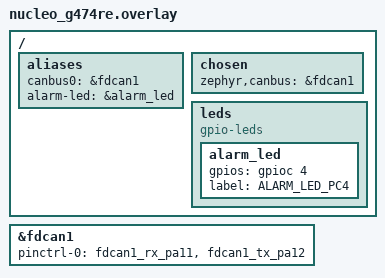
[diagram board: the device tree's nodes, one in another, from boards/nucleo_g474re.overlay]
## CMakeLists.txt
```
cmake_minimum_required(VERSION 3.20.0)

# ============================================================
# Zephyr base
# ============================================================
find_package(Zephyr REQUIRED HINTS $ENV{ZEPHYR_BASE})

project(supervisor_node_mcu LANGUAGES C CXX)

# ============================================================
# C++ STANDARD
# ============================================================
set(CMAKE_CXX_STANDARD 20)
set(CMAKE_CXX_STANDARD_REQUIRED ON)
set(CMAKE_CXX_EXTENSIONS OFF)

# ============================================================
# INCLUDE PATHS
# ============================================================
target_include_directories(app PRIVATE
    include
)

# ============================================================
# SOURCE FILES
# ============================================================
target_sources(app PRIVATE
    src/main.cpp
    src/gpio_overlay.cpp
    src/canfd.cpp
    src/heartbeat_monitoring.cpp
    src/alarm.cpp
)

# ============================================================
# COMPILER SAFETY FLAGS
# ============================================================
# NOTE on -Wpedantic: intentionally NOT requested. Zephyr 3.7 LTS's own
# public headers (kernel.h, sys_clock.h, sw_isr_table.h, toolchain/gcc.h,
# newlib's stdint.h/string.h, ...) rely on GNU C extensions (compound
# literals, anonymous structs, flexible array members, #include_next,
# named variadic macros) that are not ISO-C++-pedantic-clean. On this
# toolchain (arm-zephyr-eabi-g++, SDK 0.17.2) several of these specific
# diagnostics (-Wvariadic-macros, and two pedantic checks GCC emits with
# a bare "[-Werror]" tag rather than "[-Wpedantic]") do not respond to
# -Wno-error=pedantic, so they cannot be selectively demoted -- the only
# reliable fix is to not enable -Wpedantic in the first place. This is a
# documented limitation of building Zephyr with a strict ISO C++
# frontend, not a defect in application code.
#
# -Wno-error=format: one Zephyr __ASSERT() macro (spinlock.h) passes a
# k_spinlock* where %p expects void*; again upstream, outside app control.
#
# -Wno-error=missing-field-initializers: Zephyr's K_MSGQ_DEFINE() macro
# (Z_MSGQ_INITIALIZER in kernel.h) does not explicitly initialize every
# struct k_msgq field, relying on C99 zero-fill semantics that -Wextra
# flags under C++. Upstream macro behaviour, not application code.
target_compile_options(app PRIVATE
    -Wall
    -Wextra
    -Werror
    -Wno-error=format
    -Wno-error=missing-field-initializers
)

# ============================================================
# OPTIONAL: STRICT MISRA-LIKE BUILD HARDENING
# ============================================================
target_compile_options(app PRIVATE
    -fno-exceptions
    -fno-rtti
)
```

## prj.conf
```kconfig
# ============================================================
# BASIC KERNEL CONFIGURATION
# ============================================================
CONFIG_MAIN_STACK_SIZE=2048
CONFIG_IDLE_STACK_SIZE=512

CONFIG_SYSTEM_WORKQUEUE_STACK_SIZE=2048

CONFIG_MULTITHREADING=y
CONFIG_NUM_COOP_PRIORITIES=16
CONFIG_NUM_PREEMPT_PRIORITIES=16

CONFIG_TIMESLICING=y
CONFIG_TIMESLICE_SIZE=0

CONFIG_TICKLESS_KERNEL=y
CONFIG_SYS_CLOCK_TICKS_PER_SEC=1000


# ============================================================
# MEMORY CONFIGURATION (STRICT NO HEAP POLICY)
# ============================================================
CONFIG_HEAP_MEM_POOL_SIZE=0
CONFIG_MAIN_STACK_SIZE=2048

CONFIG_INIT_STACKS=y


# ============================================================
# C++ SUPPORT (C++20 EMBEDDED)
# ============================================================
# NOTE: CONFIG_CPLUSPLUS was removed - undefined symbol per the
# build warnings. Using CONFIG_CPP=y instead. If this still
# warns as undefined, run:
#   grep -rn "^config CPP\b" $ZEPHYR_BASE/subsys/cpp/Kconfig
# and swap in whatever symbol name it reports.
CONFIG_CPP=y
CONFIG_STD_CPP20=y

CONFIG_NEWLIB_LIBC=y
CONFIG_NEWLIB_LIBC_NANO=y

CONFIG_REQUIRES_FULL_LIBC=y


# ============================================================
# LOGGING & DEBUGGING
# ============================================================
CONFIG_LOG=y
CONFIG_LOG_MODE_IMMEDIATE=y
CONFIG_LOG_DEFAULT_LEVEL=3

CONFIG_PRINTK=y
CONFIG_ASSERT=y
CONFIG_DEBUG=y

CONFIG_THREAD_NAME=y
CONFIG_THREAD_MONITOR=y


# ============================================================
# GPIO SUPPORT
# ============================================================
CONFIG_GPIO=y


# ============================================================
# CAN / FDCAN SUPPORT (CRITICAL)
# ============================================================
CONFIG_CAN=y
CONFIG_CAN_FD_MODE=y
CONFIG_CAN_INIT_PRIORITY=80



# ============================================================
# STM32 DEVICE SUPPORT
# ============================================================
# NOTE: CONFIG_SOC_SERIES_STM32G4X / CONFIG_SOC_STM32G474XX were
# removed. These are NOT user-configurable Kconfig symbols (they
# have no "prompt" in Kconfig); they are derived automatically
# from the BOARD=nucleo_g474re selection. Setting them explicitly
# in prj.conf causes a hard Kconfig error in this Zephyr version.
CONFIG_CLOCK_CONTROL=y
CONFIG_PINCTRL=y


# ============================================================
# THREADING & SCHEDULING SAFETY
# ============================================================
# NOTE: CONFIG_PREEMPT_ENABLED and CONFIG_SCHED_DUMB removed.
# Both are silent Kconfig symbols (no prompt) in this Zephyr
# version - they're derived automatically, not user-settable.
CONFIG_THREAD_STACK_INFO=y
CONFIG_THREAD_RUNTIME_STATS=y


# ============================================================
# TIME & DELAY
# ============================================================
CONFIG_SYS_CLOCK_EXISTS=y
CONFIG_TIMEOUT_64BIT=y


# ============================================================
# SAFETY FEATURES
# ============================================================
CONFIG_FAULT_DUMP=2


# ============================================================
# OPTIONAL PERFORMANCE / CAN DEBUG
# ============================================================
CONFIG_CAN_RX_TIMESTAMP=y


# ============================================================
# BOOT CONFIG
# ============================================================
CONFIG_BOOT_BANNER=y
CONFIG_BOOT_DELAY=0
```

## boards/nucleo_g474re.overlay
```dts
/*
 * SPDX-License-Identifier: Apache-2.0
 *
 * Supervisor Node MCU
 * Board : STM32 NUCLEO-G474RE
 * RTOS  : Zephyr 3.7 LTS
 */

/ {
    aliases {
        canbus0 = &fdcan1;
        alarm-led = &alarm_led;
    };

    chosen {
        zephyr,canbus = &fdcan1;
    };
};

/* ============================================================
 * FDCAN1 CONFIGURATION (CAN BUS)
 * PA11 -> RX
 * PA12 -> TX
 * ============================================================
 */
&fdcan1 {
    status = "okay";
    pinctrl-0 = <&fdcan1_rx_pa11 &fdcan1_tx_pa12>;
    pinctrl-names = "default";
};

/* ============================================================
 * GPIO CONFIGURATION
 * PC4 -> ALARM / HEARTBEAT LED
 * ============================================================
 */
/ {
    leds {
        compatible = "gpio-leds";

        alarm_led: alarm_led {
            gpios = <&gpioc 4 GPIO_ACTIVE_HIGH>;
            label = "ALARM_LED_PC4";
        };
    };
};
```

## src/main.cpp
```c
#include <zephyr/kernel.h>
#include <zephyr/logging/log.h>

#include "gpio_overlay.hpp"
#include "canfd.hpp"
#include "heartbeat_monitoring.hpp"
#include "alarm.hpp"

LOG_MODULE_REGISTER(supervisor_node, LOG_LEVEL_INF);

/* ============================================================
 * SYSTEM LIMITS (NO MAGIC NUMBERS)
 * ============================================================
 */
static constexpr std::uint16_t kFlowMin_mL_min  = 350U;
static constexpr std::uint16_t kFlowMax_mL_min  = 450U;

static constexpr std::uint16_t kPressureMin_mmHg = 100U;
static constexpr std::uint16_t kPressureMax_mmHg = 180U;

/* ============================================================
 * SHARED SENSOR DATA (UPDATED VIA CAN RX)
 * ============================================================
 * NOTE: deliberately at TU (external) linkage, not inside an
 * unnamed namespace. canfd.cpp declares these `extern` and
 * writes to them from CanFd::DecodeRx() on CAN RX of the
 * pressure/flow frames; an unnamed namespace would give them
 * internal linkage and silently create a second, disconnected
 * copy per translation unit (link-time undefined reference).
 */
volatile std::uint16_t g_flow_value = 0U;
volatile std::uint16_t g_pressure_value = 0U;

/* ============================================================
 * THREAD STACKS
 * ============================================================
 */
K_THREAD_STACK_DEFINE(can_stack, 2048);
K_THREAD_STACK_DEFINE(safety_stack, 2048);
K_THREAD_STACK_DEFINE(hb_stack, 1024);

static struct k_thread can_thread;
static struct k_thread safety_thread;
static struct k_thread hb_thread;

/* ============================================================
 * CAN RX THREAD (100ms cycle)
 * ============================================================
 */
static void CanThread()
{
    LOG_INF("CAN thread started");

    CanFd::ProcessRx();
}

/* ============================================================
 * SAFETY EVALUATION THREAD (1 second cycle)
 * ============================================================
 * Checks:
 * - Combined fault: pressure HIGH (above max) together with
 *   flow LOW (below min) at the same time.
 * - Independent excursions of either signal alone are NOT a
 *   fault; only the simultaneous high-pressure / low-flow
 *   combination triggers STOP + ALARM.
 * ============================================================
 */
static void SafetyThread()
{
    LOG_INF("Safety thread started");

    while (true)
    {
        bool pressure_high = (g_pressure_value > kPressureMax_mmHg);
        bool flow_low       = (g_flow_value < kFlowMin_mL_min);

        bool combined_fault = pressure_high && flow_low;

        if (combined_fault)
        {
            LOG_ERR("Safety fault detected (pressure high + flow low) -> STOP MOTOR");

            CanFd::SendStopMotor();

            /* Out-of-range process value is a safety-critical fault:
             * latch PC4 ALARM until the next MCU reset. */
            Alarm::Trigger();
        }

        HeartbeatMonitoring::Evaluate();

        k_sleep(K_MSEC(1000));
    }
}

/* ============================================================
 * HEARTBEAT THREAD (1 second cycle)
 * ============================================================
 */
static void HeartbeatThread()
{
    LOG_INF("Heartbeat thread started");

    while (true)
    {
        /* If the alarm has latched, PC4 must stay solid ON and must
         * never be touched again until a hardware reset occurs. */
        if (!Alarm::IsLatched())
        {
            /* Future: LED blink + system alive monitoring */
        }

        k_sleep(K_MSEC(1000));
    }
}

/* ============================================================
 * MAIN
 * ============================================================
 */
int main()
{
    LOG_INF("Supervisor Node Booting...");

    /* INIT HARDWARE */
    if (!GpioOverlay::Init())
    {
        LOG_ERR("GPIO Init failed");
        return -1;
    }

    if (!Alarm::Init())
    {
        LOG_ERR("Alarm Init failed");
        return -1;
    }

    if (!CanFd::Init())
    {
        LOG_ERR("CAN Init failed");
        return -1;
    }

    HeartbeatMonitoring::Init();

    /* ========================================================
     * START THREADS
     * ========================================================
     */
    k_thread_create(&can_thread,
                    can_stack,
                    K_THREAD_STACK_SIZEOF(can_stack),
                    (k_thread_entry_t)CanThread,
                    nullptr, nullptr, nullptr,
                    5, 0, K_NO_WAIT);

    k_thread_create(&safety_thread,
                    safety_stack,
                    K_THREAD_STACK_SIZEOF(safety_stack),
                    (k_thread_entry_t)SafetyThread,
                    nullptr, nullptr, nullptr,
                    5, 0, K_NO_WAIT);

    k_thread_create(&hb_thread,
                    hb_stack,
                    K_THREAD_STACK_SIZEOF(hb_stack),
                    (k_thread_entry_t)HeartbeatThread,
                    nullptr, nullptr, nullptr,
                    5, 0, K_NO_WAIT);

    LOG_INF("Supervisor Node Running");

    while (true)
    {
        k_sleep(K_FOREVER);
    }

    return 0;
}
```

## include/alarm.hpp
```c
#ifndef ALARM_HPP
#define ALARM_HPP

/**
 * ============================================================
 * ALARM MODULE
 * ============================================================
 * Board : STM32 NUCLEO-G474RE
 * RTOS  : Zephyr 3.7 LTS
 *
 * Responsibility:
 * - Latch the system into an ALARM state (PC4 LED ON)
 *   whenever a safety-critical fault condition is reported
 *   by any other module (flow/pressure out of range, missed
 *   heartbeats, E-STOP, etc.).
 * - Once latched, the alarm output (PC4) stays ACTIVE and
 *   cannot be cleared by software. The only way to clear the
 *   alarm is a full MCU reset (pressing the on-board NRST
 *   button), which re-runs static initialization and Init().
 *
 * DESIGN PATTERN: State Pattern
 * - AlarmState::kArmed  -> normal operation, PC4 OFF.
 * - AlarmState::kLatched -> fault occurred, PC4 ON, and the
 *   state machine refuses every transition back to kArmed
 *   from software. Only Init() (invoked at boot / after a
 *   hardware reset) may return the state machine to kArmed.
 *
 * RULE:
 * - No business logic (sensor evaluation, CAN decoding) here.
 * - Only alarm state management + GPIO latch behaviour.
 * ============================================================
 */

#include <cstdint>

/**
 * @brief Alarm state machine states (State design pattern).
 */
enum class AlarmState : std::uint8_t
{
    kArmed   = 0U, ///< Normal operation, alarm output inactive.
    kLatched = 1U  ///< Fault latched, alarm output active until reset.
};

/**
 * @brief Latching safety alarm driver.
 *
 * Drives the ALARM LED on PC4 through GpioOverlay. Implements a
 * latch: once Trigger() is called, the alarm remains active
 * (PC4 HIGH) regardless of how many times Trigger()/Clear() is
 * subsequently called from software. The latch can only be
 * removed by a physical MCU reset (NRST button), since Init()
 * is the sole entry point that resets the internal state, and
 * Init() is only ever invoked once at boot from main().
 */
class Alarm
{
public:
    /**
     * @brief Initialize the alarm module.
     *
     * Must be called exactly once at boot, after
     * GpioOverlay::Init(). Sets the state machine to
     * AlarmState::kArmed and ensures PC4 is OFF.
     *
     * @return true if initialization succeeded.
     */
    static bool Init();

    /**
     * @brief Trigger (latch) the alarm.
     *
     * Drives PC4 HIGH and transitions the state machine to
     * AlarmState::kLatched. Safe to call repeatedly / from
     * multiple threads (e.g. SafetyThread and
     * HeartbeatMonitoring) — once latched, further calls are
     * a no-op.
     */
    static void Trigger();

    /**
     * @brief Query whether the alarm is currently latched.
     * @return true if the alarm has been triggered and not
     *         yet cleared by a hardware reset.
     */
    static bool IsLatched();

private:
    static AlarmState state_;
    static bool       initialized_;
};

#endif // ALARM_HPP
```

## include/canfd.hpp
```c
#ifndef CANFD_HPP
#define CANFD_HPP

/**
 * ============================================================
 * CANFD PROTOCOL LAYER
 * ============================================================
 * Board : STM32 NUCLEO-G474RE
 * RTOS  : Zephyr 3.7 LTS
 *
 * Responsibility:
 * - Handle CAN RX/TX
 * - Decode system messages
 * - Route data to application modules
 * - Send control commands (START / STOP / E-STOP)
 *
 * RULE:
 * - No business logic here
 * - Only protocol handling + dispatch
 * ============================================================
 */

#include <cstdint>

class CanFd
{
public:
    /**
     * @brief Initialize CAN peripheral and filters
     * @return true if success
     */
    static bool Init();

    /**
     * @brief Poll or wait for CAN messages (thread loop entry)
     */
    static void ProcessRx();

    /**
     * @brief Send START_MOTOR command (0x400)
     */
    static void SendStartMotor();

    /**
     * @brief Send STOP_MOTOR command (0x100)
     */
    static void SendStopMotor();

    /**
     * @brief Send E-STOP broadcast (0x101)
     */
    static void SendEStopBroadcast();

    /* ============================================================
     * RX QUEUE DEPTH (NO MAGIC NUMBERS)
     * ============================================================
     * Public because it is needed by the file-scope K_MSGQ_DEFINE()
     * in canfd.cpp, which must be sized at compile time outside the
     * class body. Not part of the protocol contract with other
     * modules — purely an implementation-tuning constant.
     */
    static constexpr std::uint16_t kRxQueueDepth = 10U;

private:
    /* ============================================================
     * CAN IDs (NO MAGIC NUMBERS)
     * ============================================================
     */
    static constexpr std::uint32_t kStartMotorId = 0x400U;
    static constexpr std::uint32_t kStopMotorId  = 0x100U;
    static constexpr std::uint32_t kEstopId      = 0x101U;

    static constexpr std::uint32_t kSensorHbId   = 0x200U;
    static constexpr std::uint32_t kMotorHbId    = 0x201U;
    static constexpr std::uint32_t kPressureId    = 0x300U;
    static constexpr std::uint32_t kFlowId        = 0x301U;

    /* ============================================================
     * RX QUEUE TUNING (NO MAGIC NUMBERS)
     * ============================================================
     */
    static constexpr std::uint32_t kRxPollTimeoutMs = 10U;
    static constexpr std::uint32_t kTxTimeoutMs     = 10U;

    /* Accept-all filter: zero mask matches every standard CAN ID. */
    static constexpr std::uint32_t kAcceptAllId   = 0U;
    static constexpr std::uint32_t kAcceptAllMask = 0U;

    /**
     * @brief Internal RX dispatcher
     * @param id CAN ID
     * @param data pointer to payload
     * @param len payload length
     */
    static void DecodeRx(std::uint32_t id, const std::uint8_t* data, std::uint8_t len);
};

#endif // CANFD_HPP
```

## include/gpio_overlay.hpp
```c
#ifndef GPIO_OVERLAY_HPP
#define GPIO_OVERLAY_HPP

/**
 * ============================================================
 * GPIO OVERLAY (HARDWARE ABSTRACTION LAYER)
 * ============================================================
 * Board : STM32 NUCLEO-G474RE
 * RTOS  : Zephyr 3.7 LTS
 *
 * Responsibility:
 * - Abstract all GPIO operations
 * - Control ALARM LED (PC4)
 * - Provide safe hardware API for other modules
 *
 * RULE:
 * - No direct hardware access outside this layer
 * ============================================================
 */

#include <cstdint>
#include <zephyr/drivers/gpio.h>

class GpioOverlay
{
public:
    /**
     * @brief Initialize all GPIO peripherals
     * @return true if initialization successful
     */
    static bool Init();

    /**
     * @brief Turn ON alarm LED (PC4)
     */
    static void AlarmLedOn();

    /**
     * @brief Turn OFF alarm LED (PC4)
     */
    static void AlarmLedOff();

    /**
     * @brief Toggle alarm LED (heartbeat blink)
     */
    static void AlarmLedToggle();

private:
    static constexpr std::uint8_t kAlarmLedPin = 4U;

    static const struct device* gpio_port_;

    static gpio_dt_spec alarm_led_spec_;

    static bool initialized_;
};

#endif // GPIO_OVERLAY_HPP
```

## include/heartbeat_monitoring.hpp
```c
#ifndef HEARTBEAT_MONITORING_HPP
#define HEARTBEAT_MONITORING_HPP

/**
 * ============================================================
 * HEARTBEAT MONITORING MODULE
 * ============================================================
 * Board : STM32 NUCLEO-G474RE
 * RTOS  : Zephyr 3.7 LTS
 *
 * Responsibility:
 * - Track Sensor Node heartbeat (0x200)
 * - Track Motor Node heartbeat (0x201)
 * - Detect 3-cycle timeout failure
 * - Trigger E-STOP via CAN
 *
 * RULE:
 * - No CAN decoding here
 * - Only state tracking + safety decision
 * ============================================================
 */

#include <cstdint>

class HeartbeatMonitoring
{
public:
    /**
     * @brief Initialize heartbeat counters
     */
    static void Init();

    /**
     * @brief Called when sensor heartbeat is received
     */
    static void OnSensorHeartbeat();

    /**
     * @brief Called when motor heartbeat is received
     */
    static void OnMotorHeartbeat();

    /**
     * @brief Periodic evaluation (called every 1000ms)
     */
    static void Evaluate();

private:
    static constexpr std::uint8_t kMaxMissedCount = 3U;

    static std::uint8_t sensor_missed_count_;
    static std::uint8_t motor_missed_count_;

    static bool estop_triggered_;

    static void TriggerEStop();
};

#endif // HEARTBEAT_MONITORING_HPP
```

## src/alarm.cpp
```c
#include "alarm.hpp"

#include "gpio_overlay.hpp"

#include <zephyr/kernel.h>
#include <zephyr/logging/log.h>

LOG_MODULE_REGISTER(alarm_module, LOG_LEVEL_INF);

/* ============================================================
 * STATIC MEMBER DEFINITIONS
 * ============================================================
 */
AlarmState Alarm::state_       = AlarmState::kArmed;
bool       Alarm::initialized_ = false;

/* ============================================================
 * INIT
 * ============================================================
 * Only called once, at boot, from main(). This is the only
 * place the latch is ever cleared, so the alarm can only be
 * reset by power-cycling / pressing the NRST button.
 * ============================================================
 */
bool Alarm::Init()
{
    state_ = AlarmState::kArmed;

    GpioOverlay::AlarmLedOff();

    initialized_ = true;

    return true;
}

/* ============================================================
 * TRIGGER (LATCH)
 * ============================================================
 */
void Alarm::Trigger()
{
    if (!initialized_)
    {
        return;
    }

    /* Already latched: no-op, latch can only clear on reset */
    if (state_ == AlarmState::kLatched)
    {
        return;
    }

    state_ = AlarmState::kLatched;

    GpioOverlay::AlarmLedOn();

    LOG_ERR("ALARM LATCHED -> PC4 ACTIVE (reset required to clear)");
}

/* ============================================================
 * STATE QUERY
 * ============================================================
 */
bool Alarm::IsLatched()
{
    return (state_ == AlarmState::kLatched);
}
```

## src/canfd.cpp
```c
#include "canfd.hpp"

#include "gpio_overlay.hpp"
#include "heartbeat_monitoring.hpp"

#include <zephyr/kernel.h>
#include <zephyr/drivers/can.h>
#include <zephyr/device.h>

/* ============================================================
 * EXTERNAL STATE (from main.cpp)
 * ============================================================
 */
extern volatile std::uint16_t g_flow_value;
extern volatile std::uint16_t g_pressure_value;

/* ============================================================
 * CAN DEVICE
 * ============================================================
 */
namespace
{
    const struct device* can_dev = DEVICE_DT_GET(DT_ALIAS(canbus0));

    /* Zephyr's CAN driver API is filter + callback based; there is no
     * blocking can_receive(). can_add_rx_filter_msgq() registers an
     * internal ISR-safe callback that copies matching frames straight
     * into this fixed-size queue, which ProcessRx() then drains in
     * thread context. No heap allocation: storage is static. */
    K_MSGQ_DEFINE(can_rx_msgq,
                  sizeof(struct can_frame),
                  CanFd::kRxQueueDepth,
                  alignof(struct can_frame));
}

/* ============================================================
 * INIT
 * ============================================================
 */
bool CanFd::Init()
{
    if (!device_is_ready(can_dev))
    {
        return false;
    }

    if (can_start(can_dev) != 0)
    {
        return false;
    }

    /* Route every received standard-ID frame into can_rx_msgq via
     * Zephyr's built-in ISR-safe filter callback. */
    struct can_filter filter = {};
    filter.id   = kAcceptAllId;
    filter.mask = kAcceptAllMask;

    const int filter_id = can_add_rx_filter_msgq(can_dev, &can_rx_msgq, &filter);
    if (filter_id < 0)
    {
        return false;
    }

    return true;
}

/* ============================================================
 * RX LOOP
 * ============================================================
 */
void CanFd::ProcessRx()
{
    struct can_frame frame;

    while (true)
    {
        const int ret = k_msgq_get(&can_rx_msgq, &frame, K_MSEC(kRxPollTimeoutMs));

        if (ret == 0)
        {
            DecodeRx(frame.id, frame.data, frame.dlc);
        }
    }
}

/* ============================================================
 * RX DECODER (REAL DATA INTEGRATION)
 * ============================================================
 */
void CanFd::DecodeRx(std::uint32_t id,
                     const std::uint8_t* data,
                     std::uint8_t len)
{
    (void)len;

    switch (id)
    {
        /* ====================================================
         * SENSOR HEARTBEAT
         * ====================================================
         */
        case kSensorHbId:
        {
            HeartbeatMonitoring::OnSensorHeartbeat();
            break;
        }

        /* ====================================================
         * MOTOR HEARTBEAT
         * ====================================================
         */
        case kMotorHbId:
        {
            HeartbeatMonitoring::OnMotorHeartbeat();
            break;
        }

        /* ====================================================
         * PRESSURE SENSOR (0x300)
         * ====================================================
         * Format: uint16_t (mmHg)
         */
        case kPressureId:
        {
            std::uint16_t value =
                static_cast<std::uint16_t>(data[0]) |
                (static_cast<std::uint16_t>(data[1]) << 8);

            g_pressure_value = value;
            break;
        }

        /* ====================================================
         * FLOW SENSOR (0x301)
         * ====================================================
         * Format: uint16_t (mL/min)
         */
        case kFlowId:
        {
            std::uint16_t value =
                static_cast<std::uint16_t>(data[0]) |
                (static_cast<std::uint16_t>(data[1]) << 8);

            g_flow_value = value;
            break;
        }

        default:
        {
            /* Unknown frame ignored */
            break;
        }
    }
}

/* ============================================================
 * TX FUNCTIONS
 * ============================================================
 */

void CanFd::SendStartMotor()
{
    struct can_frame frame = {};

    frame.id = kStartMotorId;
    frame.dlc = 0U;

    (void)can_send(can_dev, &frame, K_MSEC(kTxTimeoutMs), nullptr, nullptr);
}

void CanFd::SendStopMotor()
{
    struct can_frame frame = {};

    frame.id = kStopMotorId;
    frame.dlc = 0U;

    (void)can_send(can_dev, &frame, K_MSEC(kTxTimeoutMs), nullptr, nullptr);
}

void CanFd::SendEStopBroadcast()
{
    struct can_frame frame = {};

    frame.id = kEstopId;
    frame.dlc = 0U;

    (void)can_send(can_dev, &frame, K_MSEC(kTxTimeoutMs), nullptr, nullptr);
}
```

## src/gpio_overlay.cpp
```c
#include "gpio_overlay.hpp"

#include <zephyr/kernel.h>
#include <zephyr/devicetree.h>
#include <zephyr/drivers/gpio.h>

/* ============================================================
 * STATIC MEMBER DEFINITIONS
 * ============================================================
 */

const struct device* GpioOverlay::gpio_port_ = nullptr;

gpio_dt_spec GpioOverlay::alarm_led_spec_ = GPIO_DT_SPEC_GET_OR(DT_ALIAS(alarm_led), gpios, {0});

bool GpioOverlay::initialized_ = false;

/* ============================================================
 * PUBLIC API
 * ============================================================
 */

bool GpioOverlay::Init()
{
    if (initialized_)
    {
        return true;
    }

    gpio_port_ = alarm_led_spec_.port;

    if (!device_is_ready(gpio_port_))
    {
        return false;
    }

    int ret = gpio_pin_configure_dt(&alarm_led_spec_, GPIO_OUTPUT_INACTIVE);
    if (ret != 0)
    {
        return false;
    }

    /* Ensure LED starts OFF */
    gpio_pin_set_dt(&alarm_led_spec_, 0);

    initialized_ = true;
    return true;
}

void GpioOverlay::AlarmLedOn()
{
    if (!initialized_)
    {
        return;
    }

    gpio_pin_set_dt(&alarm_led_spec_, 1);
}

void GpioOverlay::AlarmLedOff()
{
    if (!initialized_)
    {
        return;
    }

    gpio_pin_set_dt(&alarm_led_spec_, 0);
}

void GpioOverlay::AlarmLedToggle()
{
    if (!initialized_)
    {
        return;
    }

    static bool state = false;
    state = !state;

    gpio_pin_set_dt(&alarm_led_spec_, static_cast<int>(state));
}
```

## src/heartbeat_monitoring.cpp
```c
#include "heartbeat_monitoring.hpp"
#include "canfd.hpp"
#include "alarm.hpp"

#include <zephyr/kernel.h>

/* ============================================================
 * STATIC VARIABLE DEFINITIONS
 * ============================================================
 */

std::uint8_t HeartbeatMonitoring::sensor_missed_count_ = 0U;
std::uint8_t HeartbeatMonitoring::motor_missed_count_  = 0U;

bool HeartbeatMonitoring::estop_triggered_ = false;

/* ============================================================
 * INIT
 * ============================================================
 */
void HeartbeatMonitoring::Init()
{
    sensor_missed_count_ = 0U;
    motor_missed_count_  = 0U;
    estop_triggered_     = false;
}

/* ============================================================
 * CALLBACK: SENSOR HEARTBEAT RECEIVED
 * ============================================================
 */
void HeartbeatMonitoring::OnSensorHeartbeat()
{
    sensor_missed_count_ = 0U;
}

/* ============================================================
 * CALLBACK: MOTOR HEARTBEAT RECEIVED
 * ============================================================
 */
void HeartbeatMonitoring::OnMotorHeartbeat()
{
    motor_missed_count_ = 0U;
}

/* ============================================================
 * E-STOP TRIGGER
 * ============================================================
 */
void HeartbeatMonitoring::TriggerEStop()
{
    if (estop_triggered_)
    {
        return;
    }

    estop_triggered_ = true;

    CanFd::SendEStopBroadcast();

    /* Heartbeat failure is a safety-critical fault: latch PC4 ALARM
     * until the next MCU reset (NRST button). */
    Alarm::Trigger();
}

/* ============================================================
 * PERIODIC EVALUATION (1 second cycle)
 * ============================================================
 * RULE:
 * - If no heartbeat received → increment counter
 * - If counter >= 3 → trigger E-STOP
 * ============================================================
 */
void HeartbeatMonitoring::Evaluate()
{
    /* Sensor heartbeat timeout */
    if (sensor_missed_count_ < kMaxMissedCount)
    {
        sensor_missed_count_++;
    }

    /* Motor heartbeat timeout */
    if (motor_missed_count_ < kMaxMissedCount)
    {
        motor_missed_count_++;
    }

    /* Check failure conditions */
    if (sensor_missed_count_ >= kMaxMissedCount ||
        motor_missed_count_ >= kMaxMissedCount)
    {
        TriggerEStop();
    }
}
```
